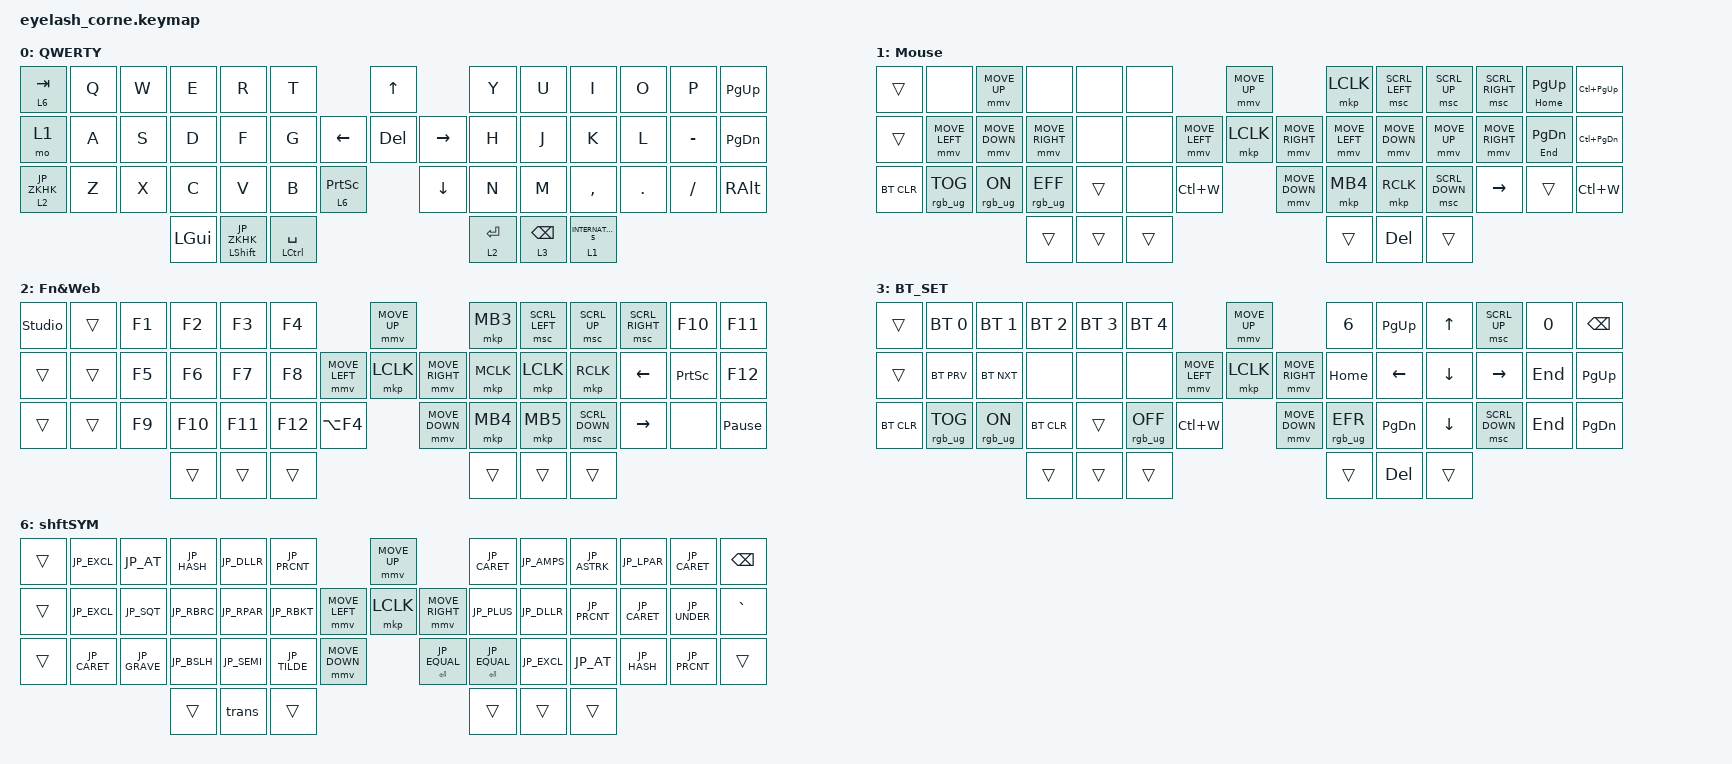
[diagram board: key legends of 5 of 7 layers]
#define ZMK_POINTING_DEFAULT_MOVE_VAL 1200  // 600
#define ZMK_POINTING_DEFAULT_SCRL_VAL 25   // 10

#include <input/processors.dtsi>
#include <zephyr/dt-bindings/input/input-event-codes.h>
#include "unicode.h"
#include "keycode_japanese.h"
#include <behaviors.dtsi>
#include <dt-bindings/zmk/backlight.h>
#include <dt-bindings/zmk/bt.h>
#include <dt-bindings/zmk/keys.h>
#include <dt-bindings/zmk/pointing.h>
#include <dt-bindings/zmk/rgb.h>

&mmv_input_listener { input-processors = <&zip_xy_scaler 2 1>; };

&msc_input_listener { input-processors = <&zip_scroll_scaler 2 1>; };

&msc {
    acceleration-exponent = <1>;      // 0
    time-to-max-speed-ms = <100>;       // 300
    delay-ms = <0>;                   // 0
};

&mmv {
    time-to-max-speed-ms = <500>;
    acceleration-exponent = <1>;
    trigger-period-ms = <16>;
};

/ {
    behaviors {
        td0: td0 {
            compatible = "zmk,behavior-tap-dance";
            display-name = "Shift/Caps Lock Tap Dance";
            #binding-cells = <0>;
            bindings = <&kp LEFT_SHIFT>, <&kp CAPS>;
        };
    };

    rgb_encoder: rgb_encoder {
        compatible = "zmk,behavior-sensor-rotate";
        #sensor-binding-cells = <0>;
        bindings = <&rgb_ug RGB_BRI>, <&rgb_ug RGB_BRD>;
    };

    scroll_encoder: scroll_encoder {
        compatible = "zmk,behavior-sensor-rotate";
        #sensor-binding-cells = <0>;
        bindings = <&msc SCRL_DOWN>, <&msc SCRL_UP>;

        tap-ms = <100>;
    };

    macros {
        gmail_address: gmail_address {
            compatible = "zmk,behavior-macro";
            #binding-cells = <0>;
            bindings =
                <&none &kp K &kp N2 &kp DOT &kp D &kp R &kp U &kp M &kp S &kp AT &kp G &kp M &kp A &kp I &kp L &kp DOT &kp C &kp O &kp M &kp TAB>,
                <&macro_tap>;

            label = "GMAIL_ADDRESS";
        };
    };

    combos {
        compatible = "zmk,combos";

        SHIFTBS {
            bindings = <&kp DELETE>;
            key-positions = <28 12>;
        };

        CtrlAltDEL {
            bindings = <&kp LA(LC(DEL))>;
            key-positions = <42 43 44>;
        };

        taskManager {
            bindings = <&kp LS(LC(ESCAPE))>;
            key-positions = <13 28>;
        };
    };

    keymap {
        compatible = "zmk,keymap";

        default_layer {
            display-name = "QWERTY";
            bindings = <
&lt 6 TAB      &kp Q  &kp W  &kp E     &kp R                 &kp T                                           &kp UP                 &kp Y        &kp U            &kp I                  &kp O    &kp P      &kp PAGE_UP
&mo 1          &kp A  &kp S  &kp D     &kp F                 &kp G                                 &kp LEFT  &kp DELETE  &kp RIGHT  &kp H        &kp J            &kp K                  &kp L    &kp MINUS  &kp PAGE_DOWN
&lt 2 JP_ZKHK  &kp Z  &kp X  &kp C     &kp V                 &kp B            &lt 6 PRINTSCREEN              &kp DOWN               &kp N        &kp M            &kp COMMA              &kp DOT  &kp FSLH   &kp RALT
                             &kp LGUI  &mt LEFT_SHIFT JP_ZKHK  &mt LCTRL SPACE                                                        &lt 2 ENTER  &lt 3 BACKSPACE  &lt 1 INTERNATIONAL_5
            >;

            sensor-bindings = <&scroll_encoder>;
        };

        MouseLayer {
            display-name = "Mouse";
            bindings = <
&trans      &none            &mmv MOVE_UP    &none            &none   &none                                &mmv MOVE_UP                     &mkp LCLK       &msc SCRL_LEFT  &msc SCRL_UP    &msc SCRL_RIGHT  &mt HOME PAGE_UP   &kp LC(PAGE_UP)
&trans      &mmv MOVE_LEFT   &mmv MOVE_DOWN  &mmv MOVE_RIGHT  &none   &none                &mmv MOVE_LEFT  &mkp LCLK       &mmv MOVE_RIGHT  &mmv MOVE_LEFT  &mmv MOVE_DOWN  &mmv MOVE_UP    &mmv MOVE_RIGHT  &mt END PAGE_DOWN  &kp LC(PAGE_DOWN)
&bt BT_CLR  &rgb_ug RGB_TOG  &rgb_ug RGB_ON  &rgb_ug RGB_EFF  &trans  &none   &kp LC(W)                    &mmv MOVE_DOWN                   &mkp MB4        &mkp RCLK       &msc SCRL_DOWN  &kp RIGHT        &trans             &kp LC(W)
                                             &trans           &trans  &trans                                                                &trans          &kp DEL         &trans
            >;

            sensor-bindings = <&inc_dec_kp LC(TAB) LS(LC(TAB))>;
        };

        layer_3 {
            display-name = "Fn&Web";
            bindings = <
&studio_unlock  &trans  &kp F1  &kp F2   &kp F3   &kp F4                                 &mmv MOVE_UP                     &mkp MB3   &msc SCRL_LEFT  &msc SCRL_UP    &msc SCRL_RIGHT  &kp F10          &kp F11
&trans          &trans  &kp F5  &kp F6   &kp F7   &kp F8                 &mmv MOVE_LEFT  &mkp LCLK       &mmv MOVE_RIGHT  &mkp MCLK  &mkp LCLK       &mkp RCLK       &kp LEFT         &kp PRINTSCREEN  &kp F12
&trans          &trans  &kp F9  &kp F10  &kp F11  &kp F12  &kp LA(F4)                    &mmv MOVE_DOWN                   &mkp MB4   &mkp MB5        &msc SCRL_DOWN  &kp RIGHT        &none            &kp PAUSE_BREAK
                                &trans   &trans   &trans                                                                  &trans     &trans          &trans
            >;

            sensor-bindings = <&inc_dec_kp LC(TAB) LS(LC(TAB))>;
        };

        BT_setting {
            display-name = "BT_SET";
            bindings = <
&trans      &bt BT_SEL 0     &bt BT_SEL 1    &bt BT_SEL 2  &bt BT_SEL 3  &bt BT_SEL 4                                  &mmv MOVE_UP                     &kp N6           &kp PG_UP  &kp UP    &msc SCRL_UP    &kp N0   &kp BSPC
&trans      &bt BT_PRV       &bt BT_NXT      &none         &none         &none                         &mmv MOVE_LEFT  &mkp LCLK       &mmv MOVE_RIGHT  &kp HOME         &kp LEFT   &kp DOWN  &kp RIGHT       &kp END  &kp PG_UP
&bt BT_CLR  &rgb_ug RGB_TOG  &rgb_ug RGB_ON  &bt BT_CLR    &trans        &rgb_ug RGB_OFF  &kp LC(W)                    &mmv MOVE_DOWN                   &rgb_ug RGB_EFR  &kp PG_DN  &kp DOWN  &msc SCRL_DOWN  &kp END  &kp PG_DN
                                             &trans        &trans        &trans                                                                         &trans           &kp DEL    &trans
            >;

            sensor-bindings = <&inc_dec_kp LC(TAB) LS(LC(TAB))>;
        };

        NumSYM {
            display-name = "NUMSYM";
            bindings = <
&trans  &kp TILDE       &kp JP_SQT    &kp JP_LBRC  &kp JP_RBRC  &kp JP_SEMI                                     &mmv MOVE_UP                       &kp NUMBER_6    &kp N7  &kp N8  &kp N9        &kp N0           &kp BSPC
&trans  &kp JP_EXCL     &kp JP_DQT    &kp JP_LPAR  &kp JP_RPAR  &kp JP_COLON                     &mmv MOVE_LEFT  &mkp LCLK        &mmv MOVE_RIGHT  &kp JP_PLUS     &kp N4  &kp N5  &kp N6        &kp JP_MINUS     &kp GRAVE
&trans  &kp QUESTION    &kp JP_GRAVE  &kp JP_LBKT  &kp JP_RBKT  &kp JP_YEN                                      &mmv MOVE_DOWN                     &mt JP_EQUAL KP_N0    &kp N1  &kp N2  &kp N3  &kp JP_SLASH  &kp RIGHT_SHIFT  
                                    &mo 6         &kp SPACE     &trans                                                                               &trans 　　　　  &trans &trans
            >;

            sensor-bindings = <&inc_dec_kp C_BRIGHTNESS_INC C_BRIGHTNESS_DEC>;
        };

        layer_4 {
            display-name = "NumPad";
            bindings = <
&kp GRAVE       &kp JP_TILDE  &kp JP_AT     &kp JP_LBRC  &kp JP_RBRC  &kp JP_SEMI                                       &kp PG_UP            &kp TAB       &kp N7     &kp N8  &kp N9  &kp JP_ASTRK  &kp BACKSPACE
&trans          &kp JP_EXCL   &kp JP_SQT    &kp JP_LPAR  &kp JP_RPAR  &kp JP_COLON                            &kp HOME  &bl BL_TOG  &kp END  &kp JP_PLUS   &kp N4     &kp N5  &kp N6  &kp JP_MINUS  &kp JP_EQUAL
&kp LEFT_SHIFT  &kp JP_CARET  &kp JP_GRAVE  &kp JP_LBKT  &kp JP_RBKT  &kp JP_BSLH    &kp C_BRIGHTNESS_AUTO              &kp PG_DN            &kp N0        &kp N1     &kp N2  &kp N3  &kp JP_SLASH  &kp JP_CARET
                                          &trans        &trans       &trans          &kp LEFT_SHIFT                                          &td0          &kp ENTER  &trans
            >;

            sensor-bindings = <&inc_dec_kp C_BRIGHTNESS_INC C_BRIGHTNESS_DEC>;
        };

        layer_6 {
            display-name = "shftSYM";
            bindings = <
&trans  &kp JP_EXCL   &kp JP_AT     &kp JP_HASH  &kp JP_DLLR  &kp JP_PRCNT                                    &mmv MOVE_UP                         &kp JP_CARET        &kp JP_AMPS  &kp JP_ASTRK  &kp JP_LPAR   &kp JP_CARET   &kp BSPC
&trans  &kp JP_EXCL   &kp JP_SQT    &kp JP_RBRC  &kp JP_RPAR  &kp JP_RBKT                     &mmv MOVE_LEFT  &mkp LCLK           &mmv MOVE_RIGHT  &kp JP_PLUS         &kp JP_DLLR  &kp JP_PRCNT  &kp JP_CARET  &kp JP_UNDER   &kp GRAVE
&trans  &kp JP_CARET  &kp JP_GRAVE  &kp JP_BSLH  &kp JP_SEMI  &kp JP_TILDE  &mmv MOVE_DOWN                    &mt ENTER JP_EQUAL                   &mt ENTER JP_EQUAL  &kp JP_EXCL  &kp JP_AT     &kp JP_HASH   &kp JP_PRCNT   &trans
                                    &trans       &kp trans    &trans                                                                               &trans        &trans  &trans
            >;

            sensor-bindings = <&inc_dec_kp C_BRIGHTNESS_INC C_BRIGHTNESS_DEC>;
        };
    };
};
